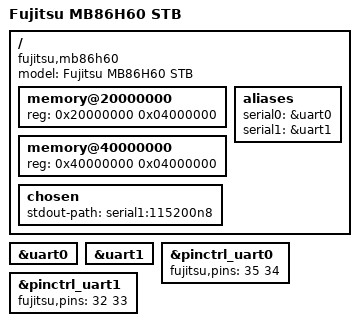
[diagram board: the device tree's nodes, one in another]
// SPDX-License-Identifier: GPL-2.0+
/*
 * Copyright (C) 2021 Thomas Schmidt <spitzbube@mail.bg>
 */

/dts-v1/;

#include "mb86h60.dtsi"

/ {
	compatible = "fujitsu,mb86h60";
	model = "Fujitsu MB86H60 STB";

	memory@20000000 {
		device_type = "memory";
		reg = <0x20000000 0x04000000>;
	};
 
	memory@40000000 {
		device_type = "memory";
		reg = <0x40000000 0x04000000>;
	};

	aliases {
		serial0 = &uart0;
		serial1 = &uart1;
	};

	chosen {
		stdout-path = "serial1:115200n8";
	};
 
};

&uart0 {
	status = "okay";
};

&uart1 {
	status = "okay";
};


&pinctrl_uart0 {
	fujitsu,pins = <35 34>;
};

&pinctrl_uart1 {
	fujitsu,pins = <32 33>;
};

